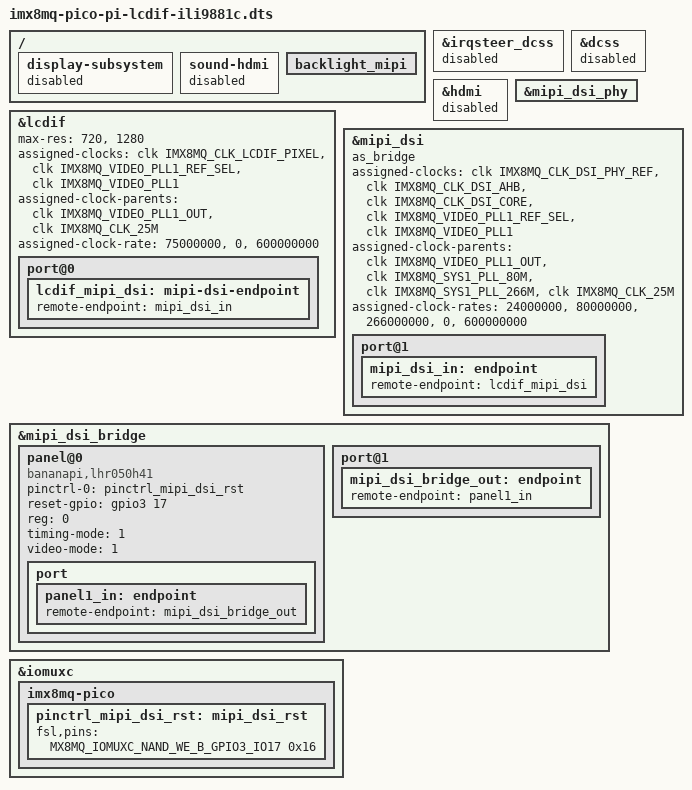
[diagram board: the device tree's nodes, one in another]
/*
 * Copyright 2018 Technexion Ltd.
 * Copyright 2017 NXP
 *
 * Author: Richard Hu <richard.hu@technexion.com>
 *
 * This program is free software; you can redistribute it and/or
 * modify it under the terms of the GNU General Public License
 * as published by the Free Software Foundation; either version 2
 * of the License, or (at your option) any later version.
 *
 * This program is distributed in the hope that it will be useful,
 * but WITHOUT ANY WARRANTY; without even the implied warranty of
 * MERCHANTABILITY or FITNESS FOR A PARTICULAR PURPOSE.  See the
 * GNU General Public License for more details.
 */

/dts-v1/;

#include "imx8mq-pico-pi.dts"

/ {
	display-subsystem {
		status = "disabled";
	};

	sound-hdmi {
		status = "disabled";
	};

	backlight_mipi {
		status = "okay";
	};
};

&irqsteer_dcss {
	status = "disabled";
};

&dcss {
	status = "disabled";
};

&hdmi {
	status = "disabled";
};

&lcdif {
	status = "okay";
	max-res = <720>, <1280>;

	/* to fix the clk */
	assigned-clocks = <&clk IMX8MQ_CLK_LCDIF_PIXEL>,
			  <&clk IMX8MQ_VIDEO_PLL1_REF_SEL>,
			  <&clk IMX8MQ_VIDEO_PLL1>;
	assigned-clock-parents = <&clk IMX8MQ_VIDEO_PLL1_OUT>,
				 <&clk IMX8MQ_CLK_25M>;
	assigned-clock-rate = <75000000>,
			      <0>,
			      <600000000>;

	port@0 {
		lcdif_mipi_dsi: mipi-dsi-endpoint {
			remote-endpoint = <&mipi_dsi_in>;
		};
	};
};

&mipi_dsi_phy {
	status = "okay";
};

&mipi_dsi {
	status = "okay";
	as_bridge;


	// sync-pol = <1>;
	/* to fix the clk */
	assigned-clocks = <&clk IMX8MQ_CLK_DSI_PHY_REF>,
			  <&clk IMX8MQ_CLK_DSI_AHB>,
			  <&clk IMX8MQ_CLK_DSI_CORE>,
			  <&clk IMX8MQ_VIDEO_PLL1_REF_SEL>,
			  <&clk IMX8MQ_VIDEO_PLL1>;
	assigned-clock-parents = <&clk IMX8MQ_VIDEO_PLL1_OUT>,
				 <&clk IMX8MQ_SYS1_PLL_80M>,
				 <&clk IMX8MQ_SYS1_PLL_266M>,
				 <&clk IMX8MQ_CLK_25M>;
	assigned-clock-rates = <24000000>,
			       <80000000>,
			       <266000000>,
			       <0>,
			       <600000000>;
	port@1 {
		mipi_dsi_in: endpoint {
			remote-endpoint = <&lcdif_mipi_dsi>;
		};
	};
};

&mipi_dsi_bridge {
	status = "okay";

	panel@0 {
		compatible = "bananapi,lhr050h41", "ilitek,ili9881c";
		pinctrl-0 = <&pinctrl_mipi_dsi_rst>;
		reset-gpio = <&gpio3 17 GPIO_ACTIVE_HIGH>;


		reg = <0>;
		timing-mode = <1>;
		video-mode = <1>;	/* 0: burst mode
					 * 1: non-burst mode with sync event
					 * 2: non-burst mode with sync pulse
					 */

		port {
			panel1_in: endpoint {
				remote-endpoint = <&mipi_dsi_bridge_out>;
			};
		};
	};

	port@1 {
		mipi_dsi_bridge_out: endpoint {
			remote-endpoint = <&panel1_in>;
		};
	};
};

&iomuxc {
	imx8mq-pico {
		pinctrl_mipi_dsi_rst: mipi_dsi_rst {
			fsl,pins = <
				MX8MQ_IOMUXC_NAND_WE_B_GPIO3_IO17	0x16   /* DSI RST */
				// MX8MQ_IOMUXC_GPIO1_IO10_GPIO1_IO10  	0x16  
			>;
		};

	};
};

/*
&i2c3 {
	polytouch: edt-ft5x06@38 {
		compatible = "edt,edt-ft5x06";
		reg = <0x38>;
		pinctrl-names = "default";
		pinctrl-0 = <&pinctrl_touch_irq &pinctrl_touch_rst>;
		interrupt-parent = <&gpio1>;
		interrupts = <7 IRQ_TYPE_EDGE_FALLING>;
		reset-gpios = <&gpio3 18 GPIO_ACTIVE_LOW>;
		touchscreen-size-x = <720>;
		touchscreen-size-y = <1280>;
	};
};
*/
